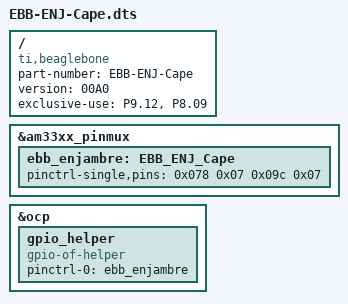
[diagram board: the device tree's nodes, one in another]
/*
*
* This program is free software; you can redistribute it and/or modify
* it under the terms of the GNU General Purpose License Version 2 as
* published by the Free Software Foundation
*
* Original from: github.com/jadonk/validation-scripts/blob/master/test-capemgr/ 
*
* Modified by Derek Molloy for the example on www.derekmolloy.ie
* that maps GPIO pins for the example
* 
* Modified by Kevin Arias for the Enjambre Robot Cape
*/

/dts-v1/;
/plugin/;

/{
       compatible = "ti,beaglebone", "ti,beaglebone-black";
       part-number = "EBB-ENJ-Cape";
       version = "00A0";
       
       exclusive-use=
             "P9.12", /*GPIO CONTROL SABERTHOOT*/
             "P8.09"; /*GPIO CONTROL SYSTEM POWER*/

       fragment@0 {
             target = <&am33xx_pinmux>;
            
             __overlay__ {
                  ebb_enjambre: EBB_ENJ_Cape {
                        pinctrl-single,pins = <
                                0x078 0x07  // P9_12 PINS$69 GPIO2 = 2 Output Mode7 pulldown
                                0x09c 0x07  // P8_09 PINS$30 GPIO1_28 = 28 Output Mode7 pulldown 
  
                               /* OUTPUT  GPIO(mode7) 0x07 pulldown, 0x17 pullup, 0x?f no pullup/down */
                               /* INPUT   GPIO(mode7) 0x27 pulldown, 0x37 pullup, 0x?f no pullup/down */
                        >;
                  };
             };
       };

       fragment@1 {
                target = <&ocp>;
                __overlay__ {
                        gpio_helper {
                                compatible = "gpio-of-helper";
                                status = "okay";
                                pinctrl-names = "default";
                                pinctrl-0 = <&ebb_enjambre>;
                        };
                };
        };


};
